# GD32H71x_72x register map
File version: 1.0
CPU: CM7 r1p2, little endian, MPU, FPU, 4 interrupt priority bits
Registers are 32-bit, read-write, reset 0x0 unless marked. A register's access mark holds for its fields unless they carry their own. Offsets are from the block's base; [hi:lo] are bit positions; {n}, {i} and the like mark numbered series.

## HAU — HAU acceleration unit
Base 0x48021400
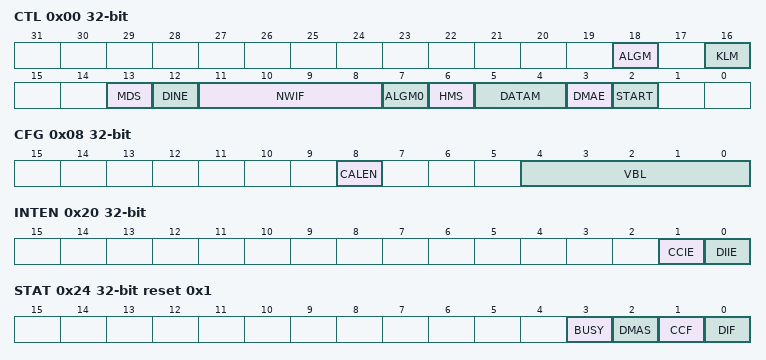
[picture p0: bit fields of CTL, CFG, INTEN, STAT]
0x00 CTL access per field — HAU control register
  [18] ALGM rw — Algorithm selection bit 1
  [16] KLM rw — Key length mode
  [13] MDS rw — Multiple DMA selection
  [12] DINE ro — DI register is not empty
  [11:8] NWIF ro — Number of words in IN FIFO
  [7] ALGM0 rw — Algorithm selection bit 0
  [6] HMS rw — HAU mode selection
  [5:4] DATAM rw — Data type mode
  [3] DMAE rw — DMA enable
  [2] START wo — Start message digest calculation
0x04 DI — HAU data input register
  [31:0] DI — Message data input
0x08 CFG access per field — HAU configuration register
  [8] CALEN wo — Digest calculation enable
  [4:0] VBL rw — Valid bits length in the last word
{0xC+4i} DO{i} ro (i=0..4) — HAU data output register
  [31:0] DO{i} — message digest result of hash algorithm
0x20 INTEN — HAU interrupt enable register
  [1] CCIE — calculation completion interrupt enable
  [0] DIIE — Data input interrupt enable
0x24 STAT ro reset 0x1 — HAU status and interrupt flag register
  [3] BUSY — Busy flag bit
  [2] DMAS — DMA status flag
  [1] CCF — Digest calculation completion flag
  [0] DIF — Data input flag
0xF8 CTXS0 reset 0x2 — Context switch register x
  [31:0] CTX0 — The complete internal status
{0xF8+4i} CTXS{i} (i=1..53) — Context switch register x
  [31:0] CTX{i} — The complete internal status
{0x310+4i} DO{i} ro (i=5..7) — HAU data output register
  [31:0] DO{i} — message digest result of hash algorithm

## HDSL0_general — HIPERFACE DSL encoder interface module
Base 0x4000DB80
Same registers: HDSL1_general 0x40002F80
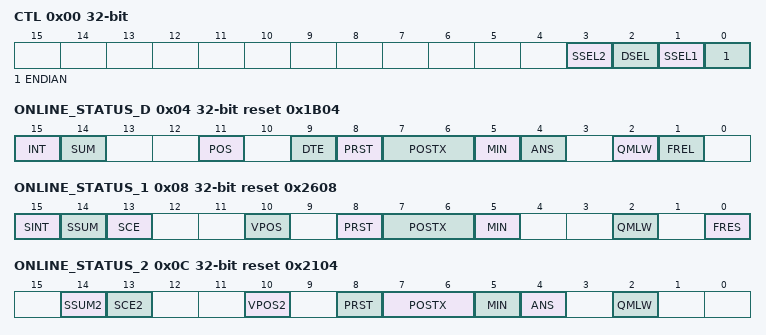
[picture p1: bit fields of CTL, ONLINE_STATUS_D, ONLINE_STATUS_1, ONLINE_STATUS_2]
0x00 CTL — HDSL control register
  [3] SSEL2 — HIPERFACE DSL unit 0 safe channel 2 interface select
  [2] DSEL — HIPERFACE DSL unit 0 driver interface select
  [1] SSEL1 — HIPERFACE DSL unit 0 safe channel 1 interface select
  [0] ENDIAN — HIPERFACE DSL unit 0 endian Mode
0x04 ONLINE_STATUS_D ro reset 0x1B04 — HDSL online status (drive) register
  [15] INT — Status of the interrupt signal
  [14] SUM — Summary byte
  [11] POS — Estimator turned on
  [9] DTE — Deviation threshold error
  [8] PRST — Protocol reset
  [7:6] POSTX — Position transmission status
  [5] MIN — Acknowledgment of message Initialization
  [4] ANS — Incorrect answer detected
  [2] QMLW — Quality monitoring at low level
  [1] FREL — Channel status for long message
0x08 ONLINE_STATUS_1 ro reset 0x2608 — HDSL online status (safe channel 1) register
  [15] SINT — Status of the interrupt signal
  [14] SSUM — Safe summary bit
  [13] SCE — CRC Error on the Safe Channel
  [10] VPOS — Safe Position Invalid
  [8] PRST — Protocol reset
  [7:6] POSTX — Position transmission status
  [5] MIN — Acknowledgment of message Initialization
  [2] QMLW — Quality monitoring at low level
  [0] FRES — Channel Status for the short message
0x0C ONLINE_STATUS_2 ro reset 0x2104 — HDSL online status (safe channel 2) register
  [14] SSUM2 — Summary byte Channel 2
  [13] SCE2 — Transmission Error Channel 2
  [10] VPOS2 — Safe Position 2 Invalid
  [8] PRST — Protocol reset
  [7:6] POSTX — Position transmission status
  [5] MIN — Acknowledgment of message Initialization
  [4] ANS — Incorrect answer detected
  [2] QMLW — Quality monitoring at low level
0x10 SYNLK ro — HDSL sync lock register
  [0] SYNLK — Position sampling resolution locked
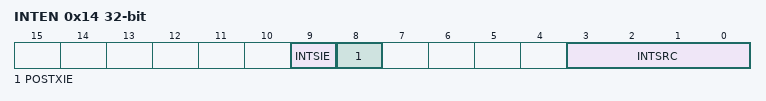
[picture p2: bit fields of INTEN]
0x14 INTEN — HDSL interrupt enable register
  [9] INTSIE — Interrupt_s enable
  [8] POSTXIE — POSTX interrupt enable
  [3:0] INTSRC — POSTX interrupt source

## HDSL0_SAFE_CHANNEL_1 — HDSL0 Safe Channel 1 Interface
Base 0x4000DA00
Same registers: HDSL1_SAFE_CHANNEL_1 0x40002E00
0x09 SAFE_EDGES 8-bit ro — HDSL safe channel 1 edge register
  [7:0] EDGES — Identification of edges in the cable signal
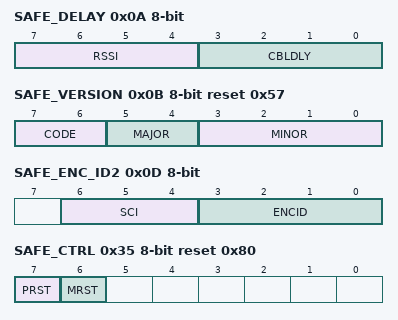
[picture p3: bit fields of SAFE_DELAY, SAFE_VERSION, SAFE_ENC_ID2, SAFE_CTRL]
0x0A SAFE_DELAY 8-bit ro — HDSL safe channel 1 run time delay register
  [7:4] RSSI — Indication of the received signal strength
  [3:0] CBLDLY — 4-bit value for cable delay
0x0B SAFE_VERSION 8-bit ro reset 0x57 — HDSL safe channel 1 version register
  [7:6] CODE — Type of module
  [5:4] MAJOR — Major release number
  [3:0] MINOR — Minor release number
0x0D SAFE_ENC_ID2 8-bit ro — HDSL safe channel 1 encoder ID 2 register
  [6:4] SCI — Indication of special characters
  [3:0] ENCID — Encoder designation code, bit 19 to bit 16
0x0E SAFE_ENC_ID1 8-bit ro — HDSL safe channel 1 encoder ID 1 register
  [7:0] ENCID — Encoder designation code, bit 15 to bit 8
0x0F SAFE_ENC_ID0 8-bit ro — HDSL safe channel 1 encoder ID 0 register
  [7:0] ENCID — Encoder designation code, bit 7 to bit 0
0x19 VPOS4 8-bit ro — HDSL safe position channel 1 byte 4 register
  [7:0] VPOS — Safe position, byte 4
0x1A VPOS3 8-bit ro — HDSL safe position channel 1 byte 3 register
  [7:0] VPOS — Safe position, byte 3
0x1B VPOS2 8-bit ro — HDSL safe position channel 1 byte 2 register
  [7:0] VPOS — Safe position, byte 2
0x1C VPOS1 8-bit ro — HDSL safe position channel 1 byte 1 register
  [7:0] VPOS — Safe position, byte 1
0x1D VPOS0 8-bit ro — HDSL safe position channel 1 byte 0 register
  [7:0] VPOS — Safe position, byte 0
0x1E VPOSCRC_H 8-bit ro — HDSL high byte position checksum channel 1 register
  [7:0] VPOSCRCH — CRC of the safe position, byte 1
0x1F VPOSCRC_L 8-bit ro — HDSL low byte position checksum channel 1 register
  [7:0] VPOSCRCL — CRC of the safe position, byte 0
0x35 SAFE_CTRL 8-bit reset 0x80 — HDSL safe system control register
  [7] PRST — Protocol reset
  [6] MRST — Message reset
0x36 SAFE_SUM 8-bit ro — HDSL safe status summary register
  [7:0] SSUM — Status summary bit
0x37 S_PC_DATA 8-bit ro — HDSL parameters channel short message register
  [7:0] SPCDATA — Short message parameter channel data
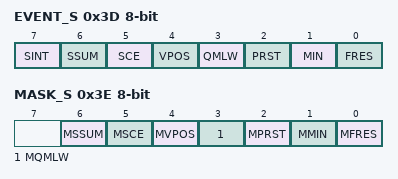
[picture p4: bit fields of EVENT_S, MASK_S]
0x3D EVENT_S 8-bit ro — HDSL safe event register
  [7] SINT — Safe interrupt status
  [6] SSUM — Remote event monitoring
  [5] SCE — Error on the Safe Channel
  [4] VPOS — Safe position error
  [3] QMLW — Quality monitoring low-value warning
  [2] PRST — Protocol reset warning
  [1] MIN — Message init
  [0] FRES — Channel free for short message
0x3E MASK_S 8-bit wo — HDSL safe event mask register
  [6] MSSUM — Mask for remote event monitoring
  [5] MSCE — Mask for transmission errors on the Safe Channel
  [4] MVPOS — Mask for safe position error
  [3] MQMLW — Mask for low-quality monitoring value warning
  [2] MPRST — Mask for protocol reset warning
  [1] MMIN — Mask for message initialization confirmation
  [0] MFRES — Mask for channel free for short message
{0x40+i} ENC_ST{i} 8-bit ro (i=0..7) — HDSL encoder status {i} register
  [7:0] ENCST — Encoder status, byte {i}
0x7C SRSSI 8-bit ro — HDSL slave RSSI register
  [2:0] SRSSI — Value of the Slave RSSI
0x7E MAIL 8-bit wo — HDSL slave mail register
  [7:0] MAIL — Slave-Mail
0x7F PING 8-bit — HDSL ping register
  [7:0] PING — Slave-Ping.
